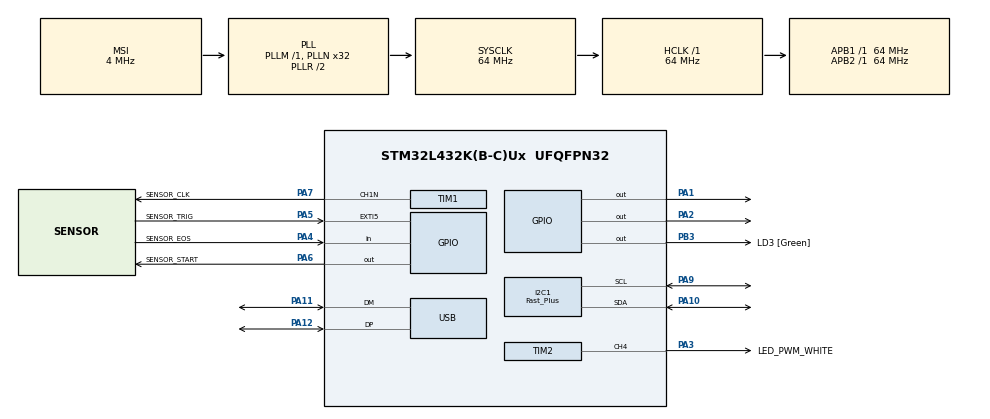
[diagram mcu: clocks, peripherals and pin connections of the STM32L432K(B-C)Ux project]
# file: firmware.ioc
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I2C1.I2C_Speed_Mode=I2C_Fast_Plus
I2C1.Timing=0x00300B29
Mcu.Family=STM32L4
Mcu.Name=STM32L432K(B-C)Ux
Mcu.Package=UFQFPN32
NVIC.EXTI9_5_IRQn=true\:0\:0\:true\:true\:true\:1\:true
NVIC.PriorityGroup=NVIC_PRIORITYGROUP_4
NVIC.USB_IRQn=true\:0\:0\:false\:false\:true\:false
PA0.GPIO_Label=MCO [High speed clock in]
PA0.Mode=HSE-External-Clock-Source-for-LittleOrca
PA0.Signal=RCC_CK_IN
PA1.Signal=GPIO_Output
PA10.Mode=I2C
PA10.Signal=I2C1_SDA
PA11.Mode=Device
PA11.Signal=USB_DM
PA12.Mode=Device
PA12.Signal=USB_DP
PA13\ (JTMS-SWDIO).GPIO_Label=SWDIO
PA13\ (JTMS-SWDIO).Mode=Serial_Wire
PA13\ (JTMS-SWDIO).Signal=SYS_JTMS-SWDIO
PA14\ (JTCK-SWCLK).GPIO_Label=SWCLK
PA14\ (JTCK-SWCLK).Mode=Serial_Wire
PA14\ (JTCK-SWCLK).Signal=SYS_JTCK-SWCLK
PA2.Signal=GPIO_Output
PA3.GPIO_Label=LED_PWM_WHITE
PA3.GPIO_Speed=GPIO_SPEED_FREQ_VERY_HIGH
PA3.Signal=S_TIM2_CH4
PA4.GPIO_Label=SENSOR_EOS
PA4.Signal=GPIO_Input
PA5.GPIO_Label=SENSOR_TRIG
PA5.Signal=GPXTI5
PA6.GPIO_Label=SENSOR_START
PA6.Signal=GPIO_Output
PA7.GPIO_Label=SENSOR_CLK
PA7.Mode=PWM Generation1 CH1N
PA7.Signal=TIM1_CH1N
PA9.Mode=I2C
PA9.Signal=I2C1_SCL
PB3\ (JTDO-TRACESWO).GPIO_Label=LD3 [Green]
PB3\ (JTDO-TRACESWO).Signal=GPIO_Output
PC14-OSC32_IN\ (PC14).Mode=LSE-External-Oscillator
PC14-OSC32_IN\ (PC14).Signal=RCC_OSC32_IN
PC15-OSC32_OUT\ (PC15).Mode=LSE-External-Oscillator
PC15-OSC32_OUT\ (PC15).Signal=RCC_OSC32_OUT
ProjectManager.HeapSize=0x200
ProjectManager.StackSize=0x400
ProjectManager.TargetToolchain=Makefile
RCC.ADCFreq_Value=48000000
RCC.AHBFreq_Value=64000000
RCC.APB1Freq_Value=64000000
RCC.APB1TimFreq_Value=64000000
RCC.APB2Freq_Value=64000000
RCC.APB2TimFreq_Value=64000000
RCC.CortexFreq_Value=64000000
RCC.HCLKFreq_Value=64000000
RCC.HSE_VALUE=8000000
RCC.HSI16_VALUE=16000000
RCC.HSI48_VALUE=48000000
RCC.HSI_VALUE=16000000
RCC.MSI_VALUE=4000000
RCC.PLLMUL=RCC_PLLMUL_4
RCC.PLLN=32
RCC.PLLSAI1N=24
RCC.SYSCLKFreq_VALUE=64000000
RCC.SYSCLKSource=RCC_SYSCLKSOURCE_PLLCLK
RCC.USBFreq_Value=48000000
RCC.VCOOutputFreq_Value=128000000
SH.S_TIM2_CH4.0=TIM2_CH4,PWM Generation4 CH4
TIM1.Channel-PWM\ Generation1\ CH1N=TIM_CHANNEL_1
TIM1.Period=125-1
TIM1.Prescaler=640-1
TIM1.Pulse-PWM\ Generation1\ CH1N=63-1
TIM2.Channel-PWM\ Generation4\ CH4=TIM_CHANNEL_4
TIM2.OCFastMode_PWM-PWM\ Generation4\ CH4=TIM_OCFAST_DISABLE
TIM2.OCPolarity_4=TIM_OCPOLARITY_HIGH
TIM2.Period=4096-1
TIM2.Prescaler=32-1
TIM2.Pulse-PWM\ Generation4\ CH4=0
USB.low_power_enable=ENABLE
USB_DEVICE.CLASS_NAME_FS=CDC
USB_DEVICE.INTERFACE_STRING_CDC_FS=Serial Interface
USB_DEVICE.LANGID_STRING=1031
USB_DEVICE.MANUFACTURER_STRING=Dr. Green
USB_DEVICE.PID_CDC_FS=0x1337
USB_DEVICE.PRODUCT_STRING_CDC_FS=VIS Specrometer
USB_DEVICE.SERIALNUMBER_STRING_CDC_FS=000000000001
USB_DEVICE.VID=0x7331
USB_DEVICE.VirtualMode=Cdc
USB_DEVICE.VirtualModeFS=Cdc_FS
VP_TIM1_VS_ClockSourceINT.Mode=Internal
VP_TIM2_VS_ClockSourceINT.Mode=Internal
VP_USB_DEVICE_VS_USB_DEVICE_CDC_FS.Mode=CDC_FS
board=NUCLEO-L432KC

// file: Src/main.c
/**
  ******************************************************************************
  * @file           : main.c
  * @brief          : Main program body
  ******************************************************************************
  * This notice applies to any and all portions of this file
  * that are not between comment pairs USER CODE BEGIN and
  * USER CODE END. Other portions of this file, whether
  * inserted by the user or by software development tools
  * are owned by their respective copyright owners.
  *
  * Copyright (c) 2018 STMicroelectronics International N.V.
  * All rights reserved.
  *
  * Redistribution and use in source and binary forms, with or without
  * modification, are permitted, provided that the following conditions are met:
  *
  * 1. Redistribution of source code must retain the above copyright notice,
  *    this list of conditions and the following disclaimer.
  * 2. Redistributions in binary form must reproduce the above copyright notice,
  *    this list of conditions and the following disclaimer in the documentation
  *    and/or other materials provided with the distribution.
  * 3. Neither the name of STMicroelectronics nor the names of other
  *    contributors to this software may be used to endorse or promote products
  *    derived from this software without specific written permission.
  * 4. This software, including modifications and/or derivative works of this
  *    software, must execute solely and exclusively on microcontroller or
  *    microprocessor devices manufactured by or for STMicroelectronics.
  * 5. Redistribution and use of this software other than as permitted under
  *    this license is void and will automatically terminate your rights under
  *    this license.
  *
  * THIS SOFTWARE IS PROVIDED BY STMICROELECTRONICS AND CONTRIBUTORS "AS IS"
  * AND ANY EXPRESS, IMPLIED OR STATUTORY WARRANTIES, INCLUDING, BUT NOT
  * LIMITED TO, THE IMPLIED WARRANTIES OF MERCHANTABILITY, FITNESS FOR A
  * PARTICULAR PURPOSE AND NON-INFRINGEMENT OF THIRD PARTY INTELLECTUAL PROPERTY
  * RIGHTS ARE DISCLAIMED TO THE FULLEST EXTENT PERMITTED BY LAW. IN NO EVENT
  * SHALL STMICROELECTRONICS OR CONTRIBUTORS BE LIABLE FOR ANY DIRECT, INDIRECT,
  * INCIDENTAL, SPECIAL, EXEMPLARY, OR CONSEQUENTIAL DAMAGES (INCLUDING, BUT NOT
  * LIMITED TO, PROCUREMENT OF SUBSTITUTE GOODS OR SERVICES; LOSS OF USE, DATA,
  * OR PROFITS; OR BUSINESS INTERRUPTION) HOWEVER CAUSED AND ON ANY THEORY OF
  * LIABILITY, WHETHER IN CONTRACT, STRICT LIABILITY, OR TORT (INCLUDING
  * NEGLIGENCE OR OTHERWISE) ARISING IN ANY WAY OUT OF THE USE OF THIS SOFTWARE,
  * EVEN IF ADVISED OF THE POSSIBILITY OF SUCH DAMAGE.
  *
  ******************************************************************************
  */
#include "main.h"
#include "stm32l4xx_hal.h"
#include "usb_device.h"

/* USER CODE BEGIN Includes */
#include "firmware.h"
/* USER CODE END Includes */

I2C_HandleTypeDef hi2c1;

TIM_HandleTypeDef htim1;
TIM_HandleTypeDef htim2;

/* USER CODE BEGIN PV */
/* Private variables ---------------------------------------------------------*/
/* USER CODE END PV */

void SystemClock_Config(void);
static void MX_GPIO_Init(void);
static void MX_I2C1_Init(void);
static void MX_TIM2_Init(void);
static void MX_TIM1_Init(void);
static void MX_NVIC_Init(void);

void HAL_TIM_MspPostInit(TIM_HandleTypeDef *htim);

/* USER CODE BEGIN PFP */
/* Private function prototypes -----------------------------------------------*/

/* USER CODE END PFP */

int main(void)
{

  /* MCU Configuration----------------------------------------------------------*/

  /* Reset of all peripherals, Initializes the Flash interface and the Systick. */
  HAL_Init();

  /* Configure the system clock */
  SystemClock_Config();

  /* Initialize all configured peripherals */
  MX_GPIO_Init();
  MX_USB_DEVICE_Init();
  MX_I2C1_Init();
  MX_TIM2_Init();
  MX_TIM1_Init();

  /* Initialize interrupts */
  MX_NVIC_Init();
  /* USER CODE BEGIN 2 */
  setup();
  /* USER CODE END 2 */

  /* Infinite loop */
  while (1)
  {

  /* USER CODE BEGIN 3 */
    loop();
  }
  /* USER CODE END 3 */

}

void SystemClock_Config(void)
{

  RCC_OscInitTypeDef RCC_OscInitStruct;
  RCC_ClkInitTypeDef RCC_ClkInitStruct;
  RCC_PeriphCLKInitTypeDef PeriphClkInit;

    /**Configure LSE Drive Capability
    */
  HAL_PWR_EnableBkUpAccess();

  __HAL_RCC_LSEDRIVE_CONFIG(RCC_LSEDRIVE_LOW);

    /**Initializes the CPU, AHB and APB busses clocks
    */
  RCC_OscInitStruct.OscillatorType = RCC_OSCILLATORTYPE_LSE|RCC_OSCILLATORTYPE_MSI;
  RCC_OscInitStruct.LSEState = RCC_LSE_ON;
  RCC_OscInitStruct.MSIState = RCC_MSI_ON;
  RCC_OscInitStruct.MSICalibrationValue = 0;
  RCC_OscInitStruct.MSIClockRange = RCC_MSIRANGE_6;
  RCC_OscInitStruct.PLL.PLLState = RCC_PLL_ON;
  RCC_OscInitStruct.PLL.PLLSource = RCC_PLLSOURCE_MSI;
  RCC_OscInitStruct.PLL.PLLM = 1;
  RCC_OscInitStruct.PLL.PLLN = 32;
  RCC_OscInitStruct.PLL.PLLP = RCC_PLLP_DIV7;
  RCC_OscInitStruct.PLL.PLLQ = RCC_PLLQ_DIV2;
  RCC_OscInitStruct.PLL.PLLR = RCC_PLLR_DIV2;
  if (HAL_RCC_OscConfig(&RCC_OscInitStruct) != HAL_OK)
  {
    _Error_Handler(__FILE__, __LINE__);
  }

    /**Initializes the CPU, AHB and APB busses clocks
    */
  RCC_ClkInitStruct.ClockType = RCC_CLOCKTYPE_HCLK|RCC_CLOCKTYPE_SYSCLK
                              |RCC_CLOCKTYPE_PCLK1|RCC_CLOCKTYPE_PCLK2;
  RCC_ClkInitStruct.SYSCLKSource = RCC_SYSCLKSOURCE_PLLCLK;
  RCC_ClkInitStruct.AHBCLKDivider = RCC_SYSCLK_DIV1;
  RCC_ClkInitStruct.APB1CLKDivider = RCC_HCLK_DIV1;
  RCC_ClkInitStruct.APB2CLKDivider = RCC_HCLK_DIV1;

  if (HAL_RCC_ClockConfig(&RCC_ClkInitStruct, FLASH_LATENCY_3) != HAL_OK)
  {
    _Error_Handler(__FILE__, __LINE__);
  }

  PeriphClkInit.PeriphClockSelection = RCC_PERIPHCLK_I2C1|RCC_PERIPHCLK_USB;
  PeriphClkInit.I2c1ClockSelection = RCC_I2C1CLKSOURCE_PCLK1;
  PeriphClkInit.UsbClockSelection = RCC_USBCLKSOURCE_PLLSAI1;
  PeriphClkInit.PLLSAI1.PLLSAI1Source = RCC_PLLSOURCE_MSI;
  PeriphClkInit.PLLSAI1.PLLSAI1M = 1;
  PeriphClkInit.PLLSAI1.PLLSAI1N = 24;
  PeriphClkInit.PLLSAI1.PLLSAI1P = RCC_PLLP_DIV7;
  PeriphClkInit.PLLSAI1.PLLSAI1Q = RCC_PLLQ_DIV2;
  PeriphClkInit.PLLSAI1.PLLSAI1R = RCC_PLLR_DIV2;
  PeriphClkInit.PLLSAI1.PLLSAI1ClockOut = RCC_PLLSAI1_48M2CLK;
  if (HAL_RCCEx_PeriphCLKConfig(&PeriphClkInit) != HAL_OK)
  {
    _Error_Handler(__FILE__, __LINE__);
  }

    /**Configure the main internal regulator output voltage
    */
  if (HAL_PWREx_ControlVoltageScaling(PWR_REGULATOR_VOLTAGE_SCALE1) != HAL_OK)
  {
    _Error_Handler(__FILE__, __LINE__);
  }

    /**Configure the Systick interrupt time
    */
  HAL_SYSTICK_Config(HAL_RCC_GetHCLKFreq()/1000);

    /**Configure the Systick
    */
  HAL_SYSTICK_CLKSourceConfig(SYSTICK_CLKSOURCE_HCLK);

    /**Enable MSI Auto calibration
    */
  HAL_RCCEx_EnableMSIPLLMode();

  /* SysTick_IRQn interrupt configuration */
  HAL_NVIC_SetPriority(SysTick_IRQn, 0, 0);
}

/**
  * @brief NVIC Configuration.
  * @retval None
  */
static void MX_NVIC_Init(void)
{
  /* EXTI9_5_IRQn interrupt configuration */
  HAL_NVIC_SetPriority(EXTI9_5_IRQn, 0, 0);
  HAL_NVIC_EnableIRQ(EXTI9_5_IRQn);
}

/* I2C1 init function */
static void MX_I2C1_Init(void)
{

  hi2c1.Instance = I2C1;
  hi2c1.Init.Timing = 0x00300B29;
  hi2c1.Init.OwnAddress1 = 0;
  hi2c1.Init.AddressingMode = I2C_ADDRESSINGMODE_7BIT;
  hi2c1.Init.DualAddressMode = I2C_DUALADDRESS_DISABLE;
  hi2c1.Init.OwnAddress2 = 0;
  hi2c1.Init.OwnAddress2Masks = I2C_OA2_NOMASK;
  hi2c1.Init.GeneralCallMode = I2C_GENERALCALL_DISABLE;
  hi2c1.Init.NoStretchMode = I2C_NOSTRETCH_DISABLE;
  if (HAL_I2C_Init(&hi2c1) != HAL_OK)
  {
    _Error_Handler(__FILE__, __LINE__);
  }

    /**Configure Analogue filter
    */
  if (HAL_I2CEx_ConfigAnalogFilter(&hi2c1, I2C_ANALOGFILTER_ENABLE) != HAL_OK)
  {
    _Error_Handler(__FILE__, __LINE__);
  }

    /**Configure Digital filter
    */
  if (HAL_I2CEx_ConfigDigitalFilter(&hi2c1, 0) != HAL_OK)
  {
    _Error_Handler(__FILE__, __LINE__);
  }

    /**I2C Fast mode Plus enable
    */
  HAL_I2CEx_EnableFastModePlus(I2C_FASTMODEPLUS_I2C1);

}

/* TIM1 init function */
static void MX_TIM1_Init(void)
{

  TIM_ClockConfigTypeDef sClockSourceConfig;
  TIM_MasterConfigTypeDef sMasterConfig;
  TIM_OC_InitTypeDef sConfigOC;
  TIM_BreakDeadTimeConfigTypeDef sBreakDeadTimeConfig;

  htim1.Instance = TIM1;
  htim1.Init.Prescaler = 640-1;
  htim1.Init.CounterMode = TIM_COUNTERMODE_UP;
  htim1.Init.Period = 125-1;
  htim1.Init.ClockDivision = TIM_CLOCKDIVISION_DIV1;
  htim1.Init.RepetitionCounter = 0;
  htim1.Init.AutoReloadPreload = TIM_AUTORELOAD_PRELOAD_DISABLE;
  if (HAL_TIM_Base_Init(&htim1) != HAL_OK)
  {
    _Error_Handler(__FILE__, __LINE__);
  }

  sClockSourceConfig.ClockSource = TIM_CLOCKSOURCE_INTERNAL;
  if (HAL_TIM_ConfigClockSource(&htim1, &sClockSourceConfig) != HAL_OK)
  {
    _Error_Handler(__FILE__, __LINE__);
  }

  if (HAL_TIM_PWM_Init(&htim1) != HAL_OK)
  {
    _Error_Handler(__FILE__, __LINE__);
  }

  sMasterConfig.MasterOutputTrigger = TIM_TRGO_RESET;
  sMasterConfig.MasterOutputTrigger2 = TIM_TRGO2_RESET;
  sMasterConfig.MasterSlaveMode = TIM_MASTERSLAVEMODE_DISABLE;
  if (HAL_TIMEx_MasterConfigSynchronization(&htim1, &sMasterConfig) != HAL_OK)
  {
    _Error_Handler(__FILE__, __LINE__);
  }

  sConfigOC.OCMode = TIM_OCMODE_PWM1;
  sConfigOC.Pulse = 63-1;
  sConfigOC.OCPolarity = TIM_OCPOLARITY_HIGH;
  sConfigOC.OCNPolarity = TIM_OCNPOLARITY_HIGH;
  sConfigOC.OCFastMode = TIM_OCFAST_DISABLE;
  sConfigOC.OCIdleState = TIM_OCIDLESTATE_RESET;
  sConfigOC.OCNIdleState = TIM_OCNIDLESTATE_RESET;
  if (HAL_TIM_PWM_ConfigChannel(&htim1, &sConfigOC, TIM_CHANNEL_1) != HAL_OK)
  {
    _Error_Handler(__FILE__, __LINE__);
  }

  sBreakDeadTimeConfig.OffStateRunMode = TIM_OSSR_DISABLE;
  sBreakDeadTimeConfig.OffStateIDLEMode = TIM_OSSI_DISABLE;
  sBreakDeadTimeConfig.LockLevel = TIM_LOCKLEVEL_OFF;
  sBreakDeadTimeConfig.DeadTime = 0;
  sBreakDeadTimeConfig.BreakState = TIM_BREAK_DISABLE;
  sBreakDeadTimeConfig.BreakPolarity = TIM_BREAKPOLARITY_HIGH;
  sBreakDeadTimeConfig.BreakFilter = 0;
  sBreakDeadTimeConfig.Break2State = TIM_BREAK2_DISABLE;
  sBreakDeadTimeConfig.Break2Polarity = TIM_BREAK2POLARITY_HIGH;
  sBreakDeadTimeConfig.Break2Filter = 0;
  sBreakDeadTimeConfig.AutomaticOutput = TIM_AUTOMATICOUTPUT_DISABLE;
  if (HAL_TIMEx_ConfigBreakDeadTime(&htim1, &sBreakDeadTimeConfig) != HAL_OK)
  {
    _Error_Handler(__FILE__, __LINE__);
  }

  HAL_TIM_MspPostInit(&htim1);

}

/* TIM2 init function */
static void MX_TIM2_Init(void)
{

  TIM_ClockConfigTypeDef sClockSourceConfig;
  TIM_MasterConfigTypeDef sMasterConfig;
  TIM_OC_InitTypeDef sConfigOC;

  htim2.Instance = TIM2;
  htim2.Init.Prescaler = 32-1;
  htim2.Init.CounterMode = TIM_COUNTERMODE_UP;
  htim2.Init.Period = 4096-1;
  htim2.Init.ClockDivision = TIM_CLOCKDIVISION_DIV1;
  htim2.Init.AutoReloadPreload = TIM_AUTORELOAD_PRELOAD_DISABLE;
  if (HAL_TIM_Base_Init(&htim2) != HAL_OK)
  {
    _Error_Handler(__FILE__, __LINE__);
  }

  sClockSourceConfig.ClockSource = TIM_CLOCKSOURCE_INTERNAL;
  if (HAL_TIM_ConfigClockSource(&htim2, &sClockSourceConfig) != HAL_OK)
  {
    _Error_Handler(__FILE__, __LINE__);
  }

  if (HAL_TIM_PWM_Init(&htim2) != HAL_OK)
  {
    _Error_Handler(__FILE__, __LINE__);
  }

  sMasterConfig.MasterOutputTrigger = TIM_TRGO_RESET;
  sMasterConfig.MasterSlaveMode = TIM_MASTERSLAVEMODE_DISABLE;
  if (HAL_TIMEx_MasterConfigSynchronization(&htim2, &sMasterConfig) != HAL_OK)
  {
    _Error_Handler(__FILE__, __LINE__);
  }

  sConfigOC.OCMode = TIM_OCMODE_PWM1;
  sConfigOC.Pulse = 0;
  sConfigOC.OCPolarity = TIM_OCPOLARITY_HIGH;
  sConfigOC.OCFastMode = TIM_OCFAST_DISABLE;
  if (HAL_TIM_PWM_ConfigChannel(&htim2, &sConfigOC, TIM_CHANNEL_4) != HAL_OK)
  {
    _Error_Handler(__FILE__, __LINE__);
  }

  HAL_TIM_MspPostInit(&htim2);

}

/** Configure pins as
        * Analog
        * Input
        * Output
        * EVENT_OUT
        * EXTI
*/
static void MX_GPIO_Init(void)
{

  GPIO_InitTypeDef GPIO_InitStruct;

  /* GPIO Ports Clock Enable */
  __HAL_RCC_GPIOC_CLK_ENABLE();
  __HAL_RCC_GPIOA_CLK_ENABLE();
  __HAL_RCC_GPIOB_CLK_ENABLE();

  /*Configure GPIO pin Output Level */
  HAL_GPIO_WritePin(GPIOA, GPIO_PIN_1|GPIO_PIN_2|SENSOR_START_Pin, GPIO_PIN_RESET);

  /*Configure GPIO pin Output Level */
  HAL_GPIO_WritePin(LD3_GPIO_Port, LD3_Pin, GPIO_PIN_RESET);

  /*Configure GPIO pins : PA1 PA2 SENSOR_START_Pin */
  GPIO_InitStruct.Pin = GPIO_PIN_1|GPIO_PIN_2|SENSOR_START_Pin;
  GPIO_InitStruct.Mode = GPIO_MODE_OUTPUT_PP;
  GPIO_InitStruct.Pull = GPIO_NOPULL;
  GPIO_InitStruct.Speed = GPIO_SPEED_FREQ_LOW;
  HAL_GPIO_Init(GPIOA, &GPIO_InitStruct);

  /*Configure GPIO pin : SENSOR_EOS_Pin */
  GPIO_InitStruct.Pin = SENSOR_EOS_Pin;
  GPIO_InitStruct.Mode = GPIO_MODE_INPUT;
  GPIO_InitStruct.Pull = GPIO_NOPULL;
  HAL_GPIO_Init(SENSOR_EOS_GPIO_Port, &GPIO_InitStruct);

  /*Configure GPIO pin : SENSOR_TRIG_Pin */
  GPIO_InitStruct.Pin = SENSOR_TRIG_Pin;
  GPIO_InitStruct.Mode = GPIO_MODE_IT_RISING;
  GPIO_InitStruct.Pull = GPIO_NOPULL;
  HAL_GPIO_Init(SENSOR_TRIG_GPIO_Port, &GPIO_InitStruct);

  /*Configure GPIO pin : LD3_Pin */
  GPIO_InitStruct.Pin = LD3_Pin;
  GPIO_InitStruct.Mode = GPIO_MODE_OUTPUT_PP;
  GPIO_InitStruct.Pull = GPIO_NOPULL;
  GPIO_InitStruct.Speed = GPIO_SPEED_FREQ_LOW;
  HAL_GPIO_Init(LD3_GPIO_Port, &GPIO_InitStruct);

}

void _Error_Handler(char *file, int line)
{
  while (1)
  {
  }
}

/************************ (C) COPYRIGHT STMicroelectronics *****END OF FILE****/
